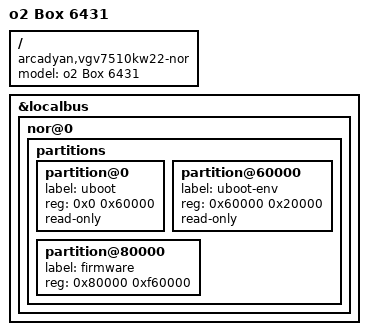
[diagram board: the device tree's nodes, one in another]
/dts-v1/;

#include "VGV7510KW22.dtsi"

/ {
	compatible = "arcadyan,vgv7510kw22-nor", "arcadyan,vgv7510kw22", "lantiq,xway", "lantiq,vr9";
	model = "o2 Box 6431";
};

&localbus {
	nor@0 {
		partitions {
			partition@0 {
				label = "uboot";
				reg = <0x0 0x60000>; /* 384 KiB */
				read-only;
			};

			partition@60000 {
				label = "uboot-env";
				reg = <0x60000 0x20000>; /* 128 KiB */
				read-only;
			};

			partition@80000 {
				label = "firmware";
				reg = <0x80000 0xf60000>; /* 15744 KiB */
			};
		};
	};
};
